# FSS_FSAS_0_FSS_FSAS_OTFA_REGS_0FC20000h register map
Vendor: Texas Instruments
Peripheral module from a debugger description file (folder am62D).
Registers are 32-bit, read-write, reset 0x0 unless marked. A register's access mark holds for its fields unless they carry their own. Offsets are as the file gives them; lines under a group give offsets from that group; [hi:lo] are bit positions; {n}, {i} and the like mark numbered series; 'fields as' and 'values as' point back to an identical list; <NAME> marks a mode.

## fss_fsas_otfa_regs
0x00 fss_fsas_otfa_regs_revid ro reset 0x47500100
  [31:0] REVID — REVID Reset Source: rst_modg_rst_n
0x04 fss_fsas_otfa_regs_scfg reset 0x2
  [1:0] IDLE_MODE — IDLE MODE Reset Source: rst_modg_rst_n
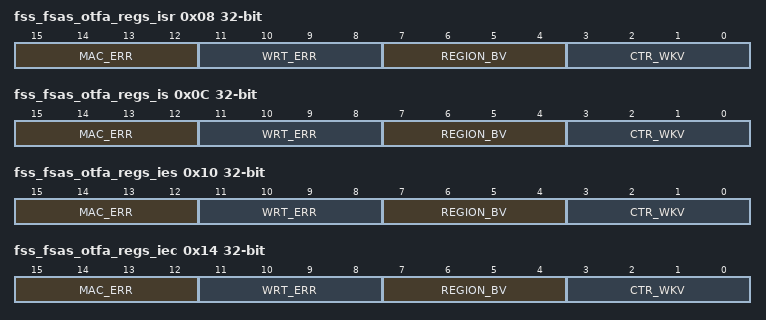
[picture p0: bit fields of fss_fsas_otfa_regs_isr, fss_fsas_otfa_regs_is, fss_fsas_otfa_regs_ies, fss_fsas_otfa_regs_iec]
0x08 fss_fsas_otfa_regs_isr
  [15:12] MAC_ERR — MAC error Reset Source: rst_modg_rst_n
  [11:8] WRT_ERR — Write error Reset Source: rst_modg_rst_n
  [7:4] REGION_BV — Region overflow boundary event caused by a burst transaction crossed a start or end of a region Reset Source: rst_modg_rst_n
  [3:0] CTR_WKV — AES mode 0 enabled region violated Wrt Once Per Wrt Key rule Reset Source: rst_modg_rst_n
0x0C fss_fsas_otfa_regs_is
  fields as fss_fsas_otfa_regs_isr
0x10 fss_fsas_otfa_regs_ies
  fields as fss_fsas_otfa_regs_isr
0x14 fss_fsas_otfa_regs_iec
  fields as fss_fsas_otfa_regs_isr
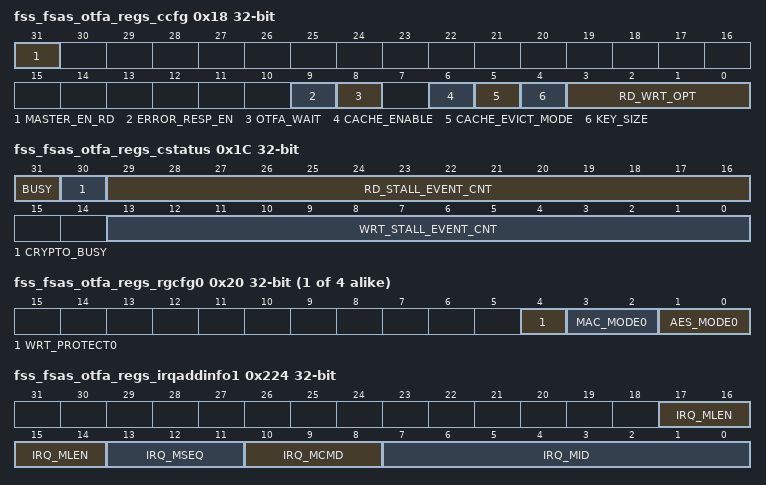
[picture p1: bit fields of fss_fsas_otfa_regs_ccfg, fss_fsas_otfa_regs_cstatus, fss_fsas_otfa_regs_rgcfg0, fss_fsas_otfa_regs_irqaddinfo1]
0x18 fss_fsas_otfa_regs_ccfg
  [31] MASTER_EN_RD — This register controls the enabling the functionality of this IP Disabled and Bypass mode active Reset Source: rst_modg_rst_n
  [9] ERROR_RESP_EN — This register controls the enabling the the ocp error response for mac errors Reset Source: rst_modg_rst_n
  [8] OTFA_WAIT — This register allows the ability to stop accepting any new transactions from getting accepted and allow the current transactions to complete Reset Source: rst_modg_rst_n
  [6] CACHE_ENABLE — MAC cache enable Reset Source: rst_modg_rst_n
  [5] CACHE_EVICT_MODE — cache evict mode Reset Source: rst_modg_rst_n
  [4] KEY_SIZE — Key Size, 0 128 Bit 1 256 Bit Reset Source: rst_modg_rst_n
  [3:0] RD_WRT_OPT — This register defines the static allocation of the AES cores to read transactions. The remainder will be allocated to write transactions Reset Source: rst_modg_rst_n
0x1C fss_fsas_otfa_regs_cstatus access not given
  [31] BUSY ro — 0 No transactions are active, crypto or none crypto 1 One or more transactions are active, crypto or none crypto Reset Source: rst_modg_rst_n
  [30] CRYPTO_BUSY ro — 0 No transactions are active, crypto or none crypto 1 One or more transactions are active, crypto or none crypto Reset Source: rst_modg_rst_n
  [29:16] RD_STALL_EVENT_CNT — rd stall event do to lack of eng Reset Source: rst_modg_rst_n (access R/W1TC)
  [13:0] WRT_STALL_EVENT_CNT — wrt stall event do to lack of eng Reset Source: rst_modg_rst_n (access R/W1TC)
{0x20+0x80*i} fss_fsas_otfa_regs_rgcfg{i} (i=0..3)
  [4] WRT_PROTECT{i} — WRT protect Reset Source: rst_modg_rst_n
  [3:2] MAC_MODE{i} — MAC mode Reset Source: rst_modg_rst_n
  [1:0] AES_MODE{i} — AES mode Reset Source: rst_modg_rst_n
{0x24+0x80*i} fss_fsas_otfa_regs_rgmacst{i} (i=0..3)
  [19:0] M_START{i} — This defines the start of the mac buffer in 4KBytes steps Reset Source: rst_modg_rst_n
{0x28+0x80*i} fss_fsas_otfa_regs_rgst{i} (i=0..3)
  [19:0] R_START{i} — This defines the start of the crypto region in 4KBytes steps Reset Source: rst_modg_rst_n
{0x2C+0x80*i} fss_fsas_otfa_regs_rgsi{i} (i=0..3)
  [19:0] R_SIZE{i} — This defines the size of the crypto region in 4KBytes steps Reset Source: rst_modg_rst_n
{0x30+4i} fss_fsas_otfa_regs_rkeye{i:02} (i=0..7)
  [31:0] R_KEY_E{i:02} — Key E Reset Source: rst_modg_rst_n
{0x50+4i} fss_fsas_otfa_regs_rkeyep{i:02} (i=0..7)
  [31:0] R_KEY_EP{i:02} — Key EP Reset Source: rst_modg_rst_n
{0x70+4i} fss_fsas_otfa_regs_rkeya{i:02} (i=0..3)
  [31:0] R_KEY_A{i:02} — Key A Reset Source: rst_modg_rst_n
{0x80+4i} fss_fsas_otfa_regs_rkeyap{i:02} (i=0..3)
  [31:0] R_KEY_AP{i:02} — Key AP Reset Source: rst_modg_rst_n
{0x90+4i} fss_fsas_otfa_regs_riv{i:02} (i=0..3)
  [31:0] R_IV{i:02} — IV Reset Source: rst_modg_rst_n
{0x88+4i} fss_fsas_otfa_regs_rkeye{i} (i=10..17)
  [31:0] R_KEY_E{i} — Key E Reset Source: rst_modg_rst_n
{0xA8+4i} fss_fsas_otfa_regs_rkeyep{i} (i=10..17)
  [31:0] R_KEY_EP{i} — Key EP Reset Source: rst_modg_rst_n
{0xC8+4i} fss_fsas_otfa_regs_rkeya{i} (i=10..13)
  [31:0] R_KEY_A{i} — Key A Reset Source: rst_modg_rst_n
{0xD8+4i} fss_fsas_otfa_regs_rkeyap{i} (i=10..13)
  [31:0] R_KEY_AP{i} — Key AP Reset Source: rst_modg_rst_n
{0xE8+4i} fss_fsas_otfa_regs_riv{i} (i=10..13)
  [31:0] R_IV{i} — IV Reset Source: rst_modg_rst_n
{0xE0+4i} fss_fsas_otfa_regs_rkeye{i} (i=20..27)
  [31:0] R_KEY_E{i} — Key E Reset Source: rst_modg_rst_n
{0x100+4i} fss_fsas_otfa_regs_rkeyep{i} (i=20..27)
  [31:0] R_KEY_EP{i} — Key EP Reset Source: rst_modg_rst_n
{0x120+4i} fss_fsas_otfa_regs_rkeya{i} (i=20..23)
  [31:0] R_KEY_A{i} — Key A Reset Source: rst_modg_rst_n
{0x130+4i} fss_fsas_otfa_regs_rkeyap{i} (i=20..23)
  [31:0] R_KEY_AP{i} — Key AP Reset Source: rst_modg_rst_n
{0x140+4i} fss_fsas_otfa_regs_riv{i} (i=20..23)
  [31:0] R_IV{i} — IV Reset Source: rst_modg_rst_n
{0x138+4i} fss_fsas_otfa_regs_rkeye{i} (i=30..37)
  [31:0] R_KEY_E{i} — Key E Reset Source: rst_modg_rst_n
{0x158+4i} fss_fsas_otfa_regs_rkeyep{i} (i=30..37)
  [31:0] R_KEY_EP{i} — Key EP Reset Source: rst_modg_rst_n
{0x178+4i} fss_fsas_otfa_regs_rkeya{i} (i=30..33)
  [31:0] R_KEY_A{i} — Key A Reset Source: rst_modg_rst_n
{0x188+4i} fss_fsas_otfa_regs_rkeyap{i} (i=30..33)
  [31:0] R_KEY_AP{i} — Key AP Reset Source: rst_modg_rst_n
{0x198+4i} fss_fsas_otfa_regs_riv{i} (i=30..33)
  [31:0] R_IV{i} — IV Reset Source: rst_modg_rst_n
0x220 fss_fsas_otfa_regs_irqaddinfo0 ro
  [31:0] IRQ_MADDR — Master Address which caused the event Reset Source: rst_modg_rst_n
0x224 fss_fsas_otfa_regs_irqaddinfo1 ro
  [17:14] IRQ_MLEN — Master LENGTH which caused the event Reset Source: rst_modg_rst_n
  [13:11] IRQ_MSEQ — Master SEQ which caused the event Reset Source: rst_modg_rst_n
  [10:8] IRQ_MCMD — Master CMD which caused the event Reset Source: rst_modg_rst_n
  [7:0] IRQ_MID — Master TAG ID which caused the event Reset Source: rst_modg_rst_n
0x228 fss_fsas_otfa_regs_maccacheinfo ro
  [15:0] CACHE_MISS_EVENT_CNT — MAC Cache Miss event cnt Reset Source: rst_modg_rst_n
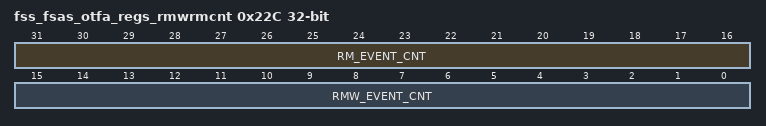
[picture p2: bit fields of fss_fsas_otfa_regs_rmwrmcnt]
0x22C fss_fsas_otfa_regs_rmwrmcnt ro
  [31:16] RM_EVENT_CNT — RM event cnt Reset Source: rst_modg_rst_n
  [15:0] RMW_EVENT_CNT — RMW event cnt Reset Source: rst_modg_rst_n
